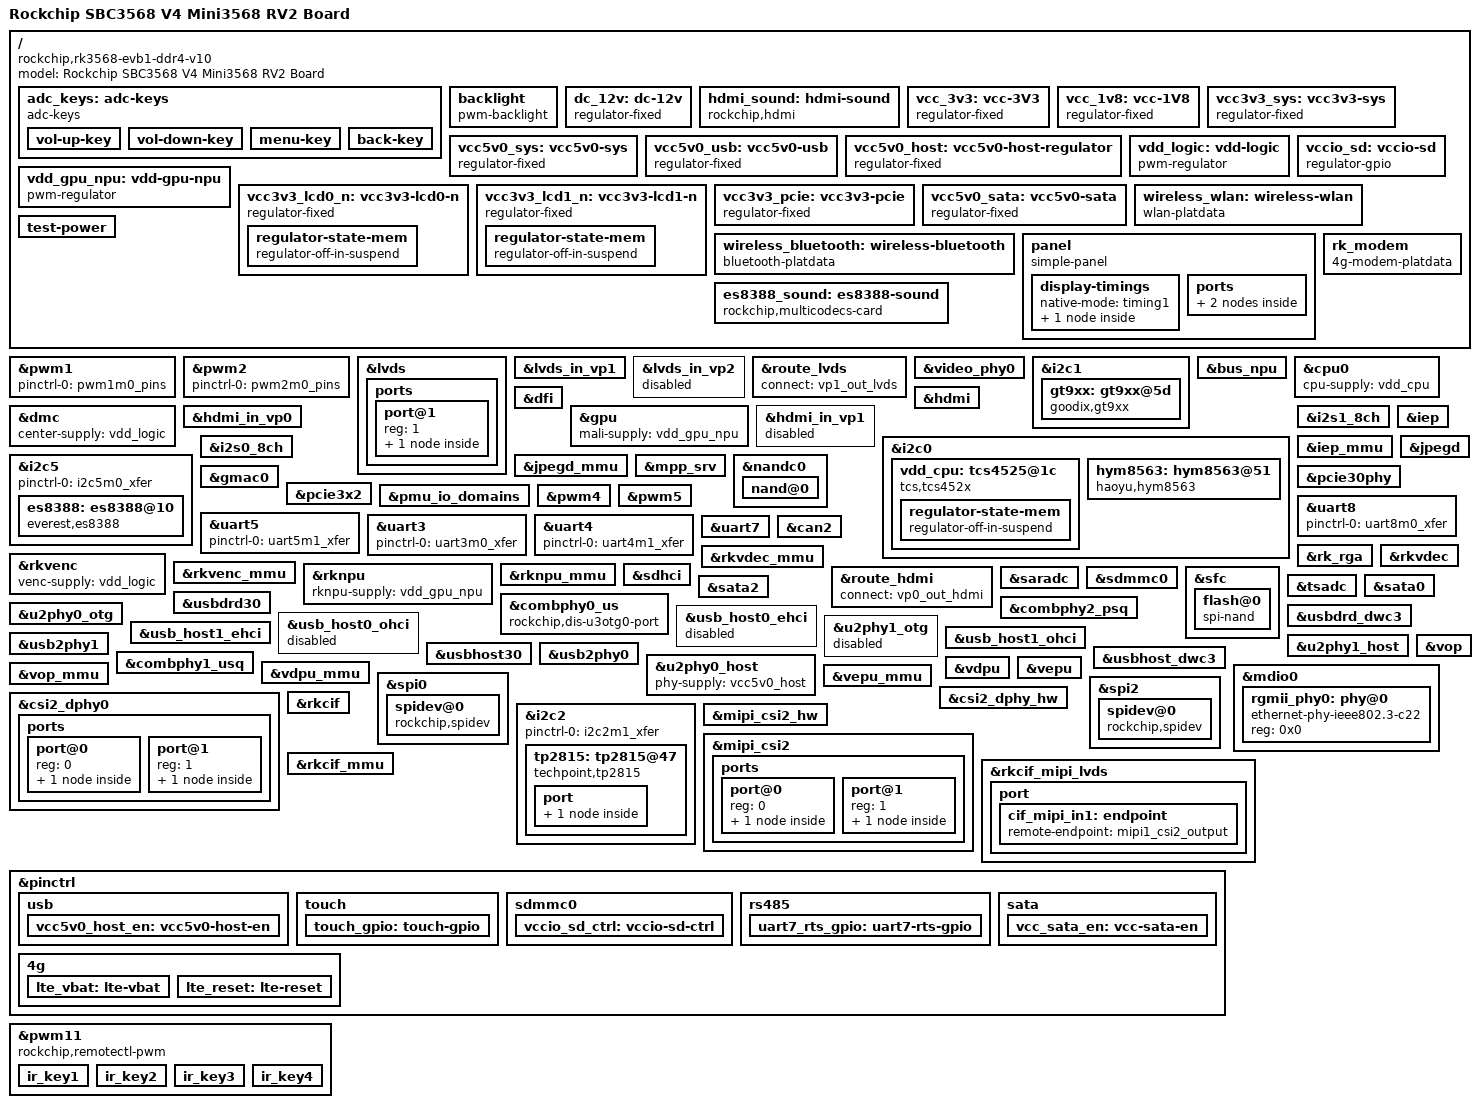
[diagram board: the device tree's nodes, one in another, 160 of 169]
// SPDX-License-Identifier: (GPL-2.0+ OR MIT)
/*
 * Copyright (c) 2020 Rockchip Electronics Co., Ltd.
 *
 */

/dts-v1/;

#include <dt-bindings/gpio/gpio.h>
#include <dt-bindings/pwm/pwm.h>
#include <dt-bindings/pinctrl/rockchip.h>
#include <dt-bindings/input/rk-input.h>
#include <dt-bindings/display/drm_mipi_dsi.h>
#include <dt-bindings/display/rockchip_vop.h>
#include <dt-bindings/display/media-bus-format.h>
#include <dt-bindings/sensor-dev.h>
#include "rk3568.dtsi"
#include "rk3568-linux.dtsi"

/ {
	model = "Rockchip SBC3568 V4 Mini3568 RV2 Board";
	compatible = "rockchip,rk3568-evb1-ddr4-v10", "rockchip,rk3568";
	/delete-node/ chosen;
	
	adc_keys: adc-keys {
		compatible = "adc-keys";
		io-channels = <&saradc 0>;
		io-channel-names = "buttons";
		keyup-threshold-microvolt = <1800000>;
		poll-interval = <100>;

		vol-up-key {
			label = "volume up";
			linux,code = <KEY_VOLUMEUP>;
			press-threshold-microvolt = <1750>;
		};

		vol-down-key {
			label = "volume down";
			linux,code = <KEY_VOLUMEDOWN>;
			press-threshold-microvolt = <297500>;
		};

		menu-key {
			label = "menu";
			linux,code = <KEY_MENU>;
			press-threshold-microvolt = <980000>;
		};

		back-key {
			label = "back";
			linux,code = <KEY_BACK>;
			press-threshold-microvolt = <1305500>;
		};
	};
	
	backlight: backlight {
		compatible = "pwm-backlight";
		pwms = <&pwm4 0 25000 0>;
		brightness-levels = <
			  0  20  20  21  21  22  22  23
			 23  24  24  25  25  26  26  27
			 27  28  28  29  29  30  30  31
			 31  32  32  33  33  34  34  35
			 35  36  36  37  37  38  38  39
			 40  41  42  43  44  45  46  47
			 48  49  50  51  52  53  54  55
			 56  57  58  59  60  61  62  63
			 64  65  66  67  68  69  70  71
			 72  73  74  75  76  77  78  79
			 80  81  82  83  84  85  86  87
			 88  89  90  91  92  93  94  95
			 96  97  98  99 100 101 102 103
			104 105 106 107 108 109 110 111
			112 113 114 115 116 117 118 119
			120 121 122 123 124 125 126 127
			128 129 130 131 132 133 134 135
			136 137 138 139 140 141 142 143
			144 145 146 147 148 149 150 151
			152 153 154 155 156 157 158 159
			160 161 162 163 164 165 166 167
			168 169 170 171 172 173 174 175
			176 177 178 179 180 181 182 183
			184 185 186 187 188 189 190 191
			192 193 194 195 196 197 198 199
			200 201 202 203 204 205 206 207
			208 209 210 211 212 213 214 215
			216 217 218 219 220 221 222 223
			224 225 226 227 228 229 230 231
			232 233 234 235 236 237 238 239
			240 241 242 243 244 245 246 247
			248 249 250 251 252 253 254 255
		>;
		default-brightness-level = <200>;
	};
	
	dc_12v: dc-12v {
		compatible = "regulator-fixed";
		regulator-name = "dc_12v";
		regulator-always-on;
		regulator-boot-on;
		regulator-min-microvolt = <12000000>;
		regulator-max-microvolt = <12000000>;
	};

	hdmi_sound: hdmi-sound {
		status = "disabled";
		compatible = "rockchip,hdmi";
		rockchip,mclk-fs = <128>;
		rockchip,card-name = "rockchip-hdmi";
		rockchip,cpu = <&i2s0_8ch>;
		rockchip,codec = <&hdmi>;
		rockchip,jack-det;
	};

	vcc_3v3: vcc-3V3 {
		compatible = "regulator-fixed";
		regulator-name = "vcc_3V3";
		regulator-always-on;
		regulator-boot-on;
		regulator-min-microvolt = <3300000>;
		regulator-max-microvolt = <3300000>;
		vin-supply = <&vcc3v3_sys>;
	};
	
	vcc_1v8: vcc-1V8 {
		compatible = "regulator-fixed";
		regulator-name = "vcc_1V8";
		regulator-always-on;
		regulator-boot-on;
		regulator-min-microvolt = <1800000>;
		regulator-max-microvolt = <1800000>;
		vin-supply = <&vcc3v3_sys>;
	};
	
	vcc3v3_sys: vcc3v3-sys {
		compatible = "regulator-fixed";
		regulator-name = "vcc3v3_sys";
		regulator-always-on;
		regulator-boot-on;
		regulator-min-microvolt = <3300000>;
		regulator-max-microvolt = <3300000>;
		vin-supply = <&dc_12v>;
	};

	vcc5v0_sys: vcc5v0-sys {
		compatible = "regulator-fixed";
		regulator-name = "vcc5v0_sys";
		regulator-always-on;
		regulator-boot-on;
		regulator-min-microvolt = <5000000>;
		regulator-max-microvolt = <5000000>;
		vin-supply = <&dc_12v>;
	};

	vcc5v0_usb: vcc5v0-usb {
		compatible = "regulator-fixed";
		regulator-name = "vcc5v0_usb";
		regulator-always-on;
		regulator-boot-on;
		regulator-min-microvolt = <5000000>;
		regulator-max-microvolt = <5000000>;
		vin-supply = <&dc_12v>;
	};

	/* usb3.0 host power en */
	vcc5v0_host: vcc5v0-host-regulator {
		compatible = "regulator-fixed";
		regulator-name = "vcc5v0_host";
		regulator-boot-on;
		regulator-always-on;
		regulator-min-microvolt = <5000000>;
		regulator-max-microvolt = <5000000>;
		enable-active-high;
		gpio = <&gpio3 RK_PB5 GPIO_ACTIVE_HIGH>;
		vin-supply = <&vcc5v0_usb>;
		pinctrl-names = "default";
		pinctrl-0 = <&vcc5v0_host_en>;
	};

	vdd_logic: vdd-logic {
		compatible = "pwm-regulator";
		pwms = <&pwm1 0 5000 1>;
		regulator-name = "vdd_logic";
		regulator-min-microvolt = <840000>;
		regulator-max-microvolt = <1040000>;
		regulator-init-microvolt = <900000>;
		regulator-always-on;
		regulator-boot-on;
		regulator-settling-time-up-us = <250>;
		pwm-supply = <&vcc5v0_sys>;
		status = "okay";
	};
	
	vdd_gpu_npu: vdd-gpu-npu {
		compatible = "pwm-regulator";
		pwms = <&pwm2 0 5000 1>;
		regulator-name = "vdd_gpu_npu";
		regulator-min-microvolt = <810000>;
		regulator-max-microvolt = <1150000>;
		regulator-init-microvolt = <900000>;
		regulator-always-on;
		regulator-boot-on;
		regulator-settling-time-up-us = <250>;
		pwm-supply = <&vcc5v0_sys>;
		status = "okay";
	};
	
	/* sd card speed swith */
	vccio_sd: vccio-sd {
  	compatible = "regulator-gpio";
  	regulator-name = "vccio_sd";
  	regulator-type = "voltage";
  	regulator-min-microvolt = <1800000>;
  	regulator-max-microvolt = <3300000>;
  	gpios = <&gpio0 RK_PB7 GPIO_ACTIVE_HIGH>;
//  	gpios-states = <1>;
  	states = <1800000 1>, 
  		       <3300000 0>; 
  	regulator-boot-on;
	  regulator-always-on;
	  pinctrl-names = "default";
	  pinctrl-0 = <&vccio_sd_ctrl>;
};

	vcc3v3_lcd0_n: vcc3v3-lcd0-n {
		compatible = "regulator-fixed";
		regulator-name = "vcc3v3_lcd0_n";
		regulator-boot-on;
		regulator-state-mem {
			regulator-off-in-suspend;
		};
	};

	vcc3v3_lcd1_n: vcc3v3-lcd1-n {
		compatible = "regulator-fixed";
		regulator-name = "vcc3v3_lcd1_n";
		regulator-boot-on;
		regulator-state-mem {
			regulator-off-in-suspend;
		};
	};

/* m.2 power en */	
	vcc3v3_pcie: vcc3v3-pcie {
		compatible = "regulator-fixed";
		regulator-name = "vcc3v3_pcie";
		regulator-min-microvolt = <3300000>;
		regulator-max-microvolt = <3300000>;
		enable-active-high;
		gpio = <&gpio3 RK_PB0 GPIO_ACTIVE_HIGH>;
		startup-delay-us = <5000>;
		pinctrl-names = "default";
	  pinctrl-0 = <&vcc_sata_en>;
	};

/* SATA power en */	
	vcc5v0_sata: vcc5v0-sata {
		compatible = "regulator-fixed";
		regulator-name = "vcc5v0_sata";
		enable-active-high;
		regulator-always-on;
    regulator-boot-on;
		gpio = <&gpio3 RK_PC1 GPIO_ACTIVE_HIGH>;
		startup-delay-us = <5000>;
	};

	wireless_wlan: wireless-wlan {
		compatible = "wlan-platdata";
		rockchip,grf = <&grf>;
		wifi_chip_type = "rtl8723du";
		status = "okay";
	};

	wireless_bluetooth: wireless-bluetooth {
		compatible = "bluetooth-platdata";
		clock-names = "ext_clock";
		status = "okay";
	};

	test-power {
		status = "okay";
	};
	
/* lvds0_ */	
	panel {
		compatible = "simple-panel";
		backlight = <&backlight>;
		power-supply = <&vcc3v3_lcd0_n>;
		enable-delay-ms = <20>;
		prepare-delay-ms = <120>;
		unprepare-delay-ms = <120>;
		disable-delay-ms = <20>;
		bus-format = <MEDIA_BUS_FMT_RGB888_1X24>;	
		rockchip,data-mapping = "vesa";
		width-mm = <217>;
		height-mm = <136>;
		rockchip,output = "lvds";
		status = "okay"; 
		
		display-timings {
			native-mode = <&timing1>;

			timing1: timing1 {
				clock-frequency = <68000000>;
				hactive = <1280>;
				vactive = <800>;
				hback-porch = <100>;
				hfront-porch = <18>;
				vback-porch = <8>;
				vfront-porch = <6>;
				hsync-len = <10>;
				vsync-len = <2>;
				hsync-active = <0>;
				vsync-active = <0>;
				de-active = <0>;
				pixelclk-active = <0>;	
							
			};
		};

		ports {
			#address-cells = <1>;
			#size-cells = <0>;

			port@0 {
				reg = <0>;
				dual-lvds-even-pixels;
				panel_in_lvds: endpoint {
					remote-endpoint = <&lvds_out_panel>;
				};
			};
		};
	};

	es8388_sound: es8388-sound {
		status = "okay";
		compatible = "rockchip,multicodecs-card";
		rockchip,card-name = "rockchip-es8388";
		rockchip,format = "i2s";
		rockchip,mclk-fs = <256>;
		rockchip,cpu = <&i2s1_8ch>;
		rockchip,codec = <&es8388>;
		rockchip,audio-routing =
			"Headphone", "LOUT2",
			"Headphone", "ROUT2",
			"Headphone", "Headphone Power",
			"Headphone", "Headphone Power",
			"LINPUT1", "Main Mic",
			"RINPUT1", "Headset Mic";
		pinctrl-names = "default";
	};
	
	rk_modem {
   	compatible="4g-modem-platdata";
   	pinctrl-names = "default";
    pinctrl-0 = <&lte_vbat &lte_reset>;
   	4G,vbat-gpio =  <&gpio3 RK_PA1 GPIO_ACTIVE_HIGH>;
   	4G,reset-gpio = <&gpio3 RK_PA7 GPIO_ACTIVE_HIGH>;
   	status = "okay";
  	};
};

&pwm1 {
	pinctrl-0 = <&pwm1m0_pins>;
	status = "okay";
};

&pwm2 {
	pinctrl-0 = <&pwm2m0_pins>;
	status = "okay";	
};


/* lvds */	

&backlight {
	status = "okay";
};


&lvds {
	status = "okay"; 

	ports {
		port@1 {
			reg = <1>;

			lvds_out_panel: endpoint {
				remote-endpoint = <&panel_in_lvds>;
			};
		};
	};
};

&lvds_in_vp1 {
	status = "okay";
};

&lvds_in_vp2 {
	status = "disabled";
};

&route_lvds {
	status = "okay";
	connect = <&vp1_out_lvds>;	
};

/* lvds phy*/	
&video_phy0 {
	status = "okay";
};

&i2c1 {
	status = "okay";
	gt9xx: gt9xx@5d {
		compatible = "goodix,gt9xx";
		reg = <0x5d>;
		pinctrl-names = "default";
		pinctrl-0 = <&touch_gpio>;
		touch-gpio = <&gpio0 RK_PC4 GPIO_ACTIVE_LOW>;
		reset-gpio = <&gpio0 RK_PA5 GPIO_ACTIVE_LOW>;
		max-x = <1280>;
		max-y = <800>;
		tp-size = <89>;
	};
};


&bus_npu {
	bus-supply = <&vdd_logic>;
	pvtm-supply = <&vdd_cpu>;
	status = "okay";
};

&cpu0 {
	cpu-supply = <&vdd_cpu>;
};

&dfi {
	status = "okay";
};

&dmc {
	center-supply = <&vdd_logic>;
	status = "okay";
};


&gpu {
	mali-supply = <&vdd_gpu_npu>;
	status = "okay";
};

&hdmi {
	status = "okay";
	rockchip,phy-table =
		<92812500  0x8009 0x0000 0x0270>,
		<165000000 0x800b 0x0000 0x026d>,
		<185625000 0x800b 0x0000 0x01ed>,
		<297000000 0x800b 0x0000 0x01ad>,
		<594000000 0x8029 0x0000 0x0088>,
		<000000000 0x0000 0x0000 0x0000>;
};

&hdmi_in_vp0 {
	status = "okay";
};

&hdmi_in_vp1 {
	status = "disabled";
};

&hdmi_sound {
	status = "okay";
};

&i2c0 {
	status = "okay";

	vdd_cpu: tcs4525@1c {
		compatible = "tcs,tcs452x";
		reg = <0x1c>;
		vin-supply = <&vcc5v0_sys>;
		regulator-compatible = "fan53555-reg";
		regulator-name = "vdd_cpu";
		regulator-min-microvolt = <712500>;
		regulator-max-microvolt = <1390000>;
		regulator-init-microvolt = <900000>;
		regulator-ramp-delay = <2300>;
		fcs,suspend-voltage-selector = <1>;
		regulator-boot-on;
		regulator-always-on;
		regulator-state-mem {
			regulator-off-in-suspend;
		};
	};
	
	hym8563: hym8563@51 {
		status = "okay";
		compatible = "haoyu,hym8563";
		reg = <0x51>;
		#clock-cells = <0>;
		interrupt-parent = <&gpio0>;
		interrupts = <27 IRQ_TYPE_EDGE_FALLING>;
		clock-frequency = <32768>;
		wakeup-source = <1>;
	};
};


/* headset */
&i2c5{
	status = "okay";
	pinctrl-names = "default";
	pinctrl-0 = <&i2c5m0_xfer>;
	
	es8388: es8388@10 {
		status = "okay";
		#sound-dai-cells = <0>;
		compatible = "everest,es8388", "everest,es8323";
		reg = <0x10>;
		clocks = <&cru I2S1_MCLKOUT>;
		clock-names = "mclk";
		assigned-clocks = <&cru I2S1_MCLKOUT>, <&cru I2S1_MCLK_TX_IOE>;
		assigned-clock-rates = <12288000>;
		assigned-clock-parents = <&cru I2S1_MCLKOUT_TX>, <&cru I2S1_MCLKOUT_TX>;
		pinctrl-names = "default";
		pinctrl-0 = <&i2s1m0_mclk>;
		everest,differential-input = <1>;
		everest,dac-output = <2>;
	};
};

&i2s1_8ch {
	status = "okay";
	rockchip,trcm-sync-tx-only;
	pinctrl-names = "default";
	pinctrl-0 = <&i2s1m0_sclktx
		     &i2s1m0_lrcktx
		     &i2s1m0_sdi0
		     &i2s1m0_sdo0>;
};

/* hdmi sound phy */
&i2s0_8ch {
	status = "okay";
};

&iep {
	status = "okay";
};

&iep_mmu {
	status = "okay";
};

&jpegd {
	status = "okay";
};

&jpegd_mmu {
	status = "okay";
};

&mpp_srv {
	status = "okay";
};

&nandc0 {
	#address-cells = <1>;
	#size-cells = <0>;
	status = "okay";

	nand@0 {
		reg = <0>;
		nand-bus-width = <8>;
		nand-ecc-mode = "hw";
		nand-ecc-strength = <16>;
		nand-ecc-step-size = <1024>;
	};
};

/***Net interface***/
&gmac0 {
	phy-mode = "rgmii";
	clock_in_out = "output";

	snps,reset-gpio = <&gpio0 RK_PA3 GPIO_ACTIVE_LOW>;
	snps,reset-active-low;
	/* Reset time is 20ms, 100ms for rtl8211f */
	snps,reset-delays-us = <0 20000 100000>;

	assigned-clocks = <&cru SCLK_GMAC0_RX_TX>, <&cru SCLK_GMAC0>;
	assigned-clock-parents = <&cru SCLK_GMAC0_RGMII_SPEED>, <&cru CLK_MAC0_2TOP>;
	assigned-clock-rates = <0>, <125000000>;

	pinctrl-names = "default";
	pinctrl-0 = <&gmac0_miim
		     &gmac0_tx_bus2
		     &gmac0_rx_bus2
		     &gmac0_rgmii_clk
		     &gmac0_rgmii_bus>;

	tx_delay = <0x3c>;
	rx_delay = <0x2f>;

	phy-handle = <&rgmii_phy0>;
	status = "okay";
};

/* m.2 phy */
&pcie30phy {
	status = "okay";
};

/* m.2 ssd */
&pcie3x2 {
	reset-gpios = <&gpio0 RK_PC6 GPIO_ACTIVE_HIGH>;
	vpcie3v3-supply = <&vcc3v3_pcie>;
	status = "okay";
};


 /*
  * There are 10 independent IO domains in RK3566/RK3568, including PMUIO[0:2] and VCCIO[1:7].
  * 1/ PMUIO0 and PMUIO1 are fixed-level power domains which cannot be configured;
  * 2/ PMUIO2 and VCCIO1,VCCIO[3:7] domains require that their hardware power supply voltages
  *    must be consistent with the software configuration correspondingly
  *	a/ When the hardware IO level is connected to 1.8V, the software voltage configuration
  *	   should also be configured to 1.8V accordingly;
  *	b/ When the hardware IO level is connected to 3.3V, the software voltage configuration
  *	   should also be configured to 3.3V accordingly;
  * 3/ VCCIO2 voltage control selection (0xFDC20140)
  *	BIT[0]: 0x0: from GPIO_0A7 (default)
  *	BIT[0]: 0x1: from GRF
  *    Default is determined by Pin FLASH_VOL_SEL/GPIO0_A7:
  *	L:VCCIO2 must supply 3.3V
  *	H:VCCIO2 must supply 1.8V
  */
&pmu_io_domains {
	status = "okay";
	pmuio2-supply = <&vcc_3v3>;
	vccio1-supply = <&vcc_3v3>;
	vccio3-supply = <&vccio_sd>;
	vccio4-supply = <&vcc_1v8>;
	vccio5-supply = <&vcc_3v3>;
	vccio6-supply = <&vcc_1v8>;
	vccio7-supply = <&vcc_3v3>;
};

&pwm4 {
	status = "okay";
};

&pwm5 {
	status = "okay";
};


/*  uart   */
&uart8 {
  status = "okay";
  pinctrl-names = "default";
  pinctrl-0 = <&uart8m0_xfer>;
};

&uart5 {
  status = "okay";
  pinctrl-names = "default";
  pinctrl-0 = <&uart5m1_xfer>;
};

&uart3 {
  status = "okay";
  pinctrl-names = "default";
  pinctrl-0 = <&uart3m0_xfer>;
};

&uart4 {
  status = "okay";
  pinctrl-names = "default";
  pinctrl-0 = <&uart4m1_xfer>;
};

/* rs485 */
&uart7 {
  status = "okay";
  pinctrl-names = "default";
  pinctrl-0 = <&uart7m1_xfer &uart7_rts_gpio>;
  rs485-de-gpios = <&gpio4 RK_PC2 GPIO_ACTIVE_HIGH>;
  linux,rs485-enabled-at-boot-time;
  //rs485-rts-active-low;
};

/* can */
&can2 {
  assigned-clocks = <&cru CLK_CAN2>;
  assigned-clock-rates = <150000000>;
  pinctrl-names = "default";
  pinctrl-0 = <&can2m1_pins>;
  status = "okay";
};



&rk_rga {
	status = "okay";
};

&rkvdec {
	status = "okay";
};

&rkvdec_mmu {
	status = "okay";
};

&rkvenc {
	venc-supply = <&vdd_logic>;
	status = "okay";
};

&rkvenc_mmu {
	status = "okay";
};

&rknpu {
	rknpu-supply = <&vdd_gpu_npu>;
	status = "okay";
};

&rknpu_mmu {
	status = "okay";
};

&route_hdmi {
	status = "okay";
	connect = <&vp0_out_hdmi>;
};

&saradc {
	status = "okay";
};

&sdhci {
	bus-width = <8>;
	no-sdio;
	no-sd;
	non-removable;
	max-frequency = <200000000>;
	full-pwr-cycle-in-suspend;
	status = "okay";
};

/* sd card */
&sdmmc0 {
	max-frequency = <150000000>;
	no-sdio;
	no-mmc;
	bus-width = <4>;
	cap-mmc-highspeed;
	cap-sd-highspeed;
	disable-wp;
	sd-uhs-sdr104;
	vmmc-supply = <&vcc_3v3>;
	vqmmc-supply = <&vccio_sd>;
	pinctrl-names = "default";
	pinctrl-0 = <&sdmmc0_bus4 &sdmmc0_clk &sdmmc0_cmd &sdmmc0_det>;
	status = "okay";
};

&sfc {
	status = "okay";

	flash@0 {
		compatible = "spi-nand";
		reg = <0>;
		spi-max-frequency = <75000000>;
		spi-rx-bus-width = <4>;
		spi-tx-bus-width = <1>;
	};
};


&tsadc {
	status = "okay";
};

/* sata0 */
&sata0 {
  status = "okay";
};

/* USB 3.0 OTG/SATA Combo PHY_0 */
&combphy0_us {
	rockchip,dis-u3otg0-port;
	status = "okay";
};

/* sata2 */
&sata2 {
  status = "okay";
};

/* sata2 phy*/
&combphy2_psq {
	status = "okay";
};


/* USB 3.0 OTG controller */
&usbdrd30 {
	status = "okay";
};

&u2phy0_otg {
	status = "okay";
};

/* USB OTG */
&usbdrd_dwc3 {  
	phys = <&u2phy0_otg>;
  phy-names = "usb2-phy";
  extcon = <&usb2phy0>;
  maximum-speed = "high-speed";
  snps,dis_u2_susphy_quirk;
  snps,usb2-lpm-disable;
  status = "okay";
};


/* USB 2.0 Host_2 null */
&usb_host0_ehci {
	status = "disabled";
};

&usb_host0_ohci {
	status = "disabled";
};

&u2phy1_otg {
	status = "disabled";
};

/* USB 2.0 Host_3 */
/* mini pcie 4G   */

&usb_host1_ehci {
	status = "okay";
};

&usb_host1_ohci {
	status = "okay";
};

&usb2phy1 {
	status = "okay";
};

&u2phy1_host {
	status = "okay";
};



/* usb3.0 host */
&usbhost30 {
	status = "okay";
};

&usbhost_dwc3 {
	status = "okay";
};

&usb2phy0 {
	status = "okay";
};

&u2phy0_host {
	phy-supply = <&vcc5v0_host>;
	status = "okay";
};

/* USB 3.0 Host/SATA/QSGMII Combo PHY_1 */
&combphy1_usq {
	status = "okay";
};

&vdpu {
	status = "okay";
};

&vdpu_mmu {
	status = "okay";
};

&vepu {
	status = "okay";
};

&vepu_mmu {
	status = "okay";
};

&vop {
	status = "okay";
	vop-supply = <&vdd_logic>;
	assigned-clocks = <&cru DCLK_VOP0>, <&cru DCLK_VOP1>, <&cru DCLK_VOP2>;
	assigned-clock-parents = <&pmucru PLL_HPLL>, <&cru PLL_VPLL>, <&cru PLL_GPLL>;
};

&vop_mmu {
	status = "okay";
};


/* ethernet */
&gmac0 {
	phy-mode = "rgmii";
	clock_in_out = "output";

	snps,reset-gpio = <&gpio0 RK_PA3 GPIO_ACTIVE_LOW>;
	snps,reset-active-low;
	/* Reset time is 20ms, 100ms for rtl8211f */
	snps,reset-delays-us = <0 20000 100000>;

	assigned-clocks = <&cru SCLK_GMAC0_RX_TX>, <&cru SCLK_GMAC0>;
	assigned-clock-parents = <&cru SCLK_GMAC0_RGMII_SPEED>, <&cru CLK_MAC0_2TOP>;
	assigned-clock-rates = <0>, <125000000>;

	pinctrl-names = "default";
	pinctrl-0 = <&gmac0_miim
		     &gmac0_tx_bus2
		     &gmac0_rx_bus2
		     &gmac0_rgmii_clk
		     &gmac0_rgmii_bus>;

	tx_delay = <0x3c>;
	rx_delay = <0x2f>;

	phy-handle = <&rgmii_phy0>;
	status = "okay";
};

&mdio0 {
	rgmii_phy0: phy@0 {
		compatible = "ethernet-phy-ieee802.3-c22";
		reg = <0x0>;
	};
};

&spi0 {
  status = "okay";
  #address-cells = <1>;
  #size-cells = <0>;
  pinctrl-names = "default";
  pinctrl-0 = <&spi0m1_cs0 &spi0m1_pins>;
  max-freq = <50000000>;

   spidev@0 {
    compatible = "rockchip,spidev";
    status = "okay";
    reg = <0>;
    spi-max-frequency = <50000000>;
  };
};

&spi2 {
  status = "okay";
  #address-cells = <1>;
  #size-cells = <0>;
  pinctrl-names = "default";
  pinctrl-0 = <&spi2m1_cs0 &spi2m1_pins>;
  max-freq = <50000000>;

  spidev@0 {
    compatible = "rockchip,spidev";
    status = "okay";
    reg = <0>;
    spi-max-frequency = <50000000>;
  };
}; 

/* tp2855 */
&csi2_dphy0 {
	status = "okay";

	ports {
		#address-cells = <1>;
		#size-cells = <0>;
		port@0 {
			reg = <0>;
			#address-cells = <1>;
			#size-cells = <0>;

			mipi_dphy0_in_tp2815: endpoint@1 {
				reg = <1>;
				remote-endpoint = <&tp2815_out0>;
				data-lanes = <1 2 3 4>;
			};
		};
		port@1 {
			reg = <1>;
			#address-cells = <1>;
			#size-cells = <0>;

			csidphy0_out: endpoint@0 {
				reg = <0>;
				remote-endpoint = <&mipi1_csi2_input>;
			};
		};
	};
};

&csi2_dphy_hw {
	status = "okay";
};

&i2c2 {
	status = "okay";
	pinctrl-names = "default";
  pinctrl-0 = <&i2c2m1_xfer>;
	tp2815: tp2815@47 {
		compatible = "techpoint,tp2815";
		status = "okay";
		reg = <0x47>;
		clocks = <&cru CLK_CIF_OUT>;
		clock-names = "xvclk";
		power-domains = <&power RK3568_PD_VI>;
		reset-gpios = <&gpio4 RK_PB1 GPIO_ACTIVE_LOW>;
		rockchip,camera-module-index = <0>;
		rockchip,camera-module-facing = "back";
		rockchip,camera-module-name = "default";
		rockchip,camera-module-lens-name = "default";

		port {
					tp2815_out0: endpoint {
									remote-endpoint = < &mipi_dphy0_in_tp2815>;
									data-lanes = <1 2 3 4>;
						};
				};
		};
};


&mipi_csi2_hw {
  status = "okay";
};

&mipi_csi2 {
	status = "okay";

	ports {
		#address-cells = <1>;
		#size-cells = <0>;

		port@0 {
			reg = <0>;
			#address-cells = <1>;
			#size-cells = <0>;

			mipi1_csi2_input: endpoint@1 {
				reg = <1>;
				remote-endpoint = <&csidphy0_out>;
			};
		};

		port@1 {
			reg = <1>;
			#address-cells = <1>;
			#size-cells = <0>;

			mipi1_csi2_output: endpoint@0 {
				reg = <0>;
				remote-endpoint = <&cif_mipi_in1>;
			};
		};
	};
};

&rkcif {
	status = "okay";
};

&rkcif_mipi_lvds {
	status = "okay";

	port {
		cif_mipi_in1: endpoint {
			remote-endpoint = <&mipi1_csi2_output>;
		};
	};
};

&rkcif_mmu {
	status = "okay";
};
 

&pinctrl {

	usb {
		vcc5v0_host_en: vcc5v0-host-en {
			rockchip,pins = <3 RK_PB5 RK_FUNC_GPIO &pcfg_pull_none>;
		};
	};

	touch {
		touch_gpio: touch-gpio {
			rockchip,pins =
				<0 RK_PC4 RK_FUNC_GPIO &pcfg_pull_up>,
				<0 RK_PA5 RK_FUNC_GPIO &pcfg_pull_none>;
		};
	};
	
	sdmmc0 {
		vccio_sd_ctrl: vccio-sd-ctrl {
			rockchip,pins = <0 RK_PB7 RK_FUNC_GPIO &pcfg_pull_none>;
		};
	}; 
	
	rs485 {
		uart7_rts_gpio: uart7-rts-gpio {
			rockchip,pins = <4 RK_PC2 RK_FUNC_GPIO &pcfg_pull_none>;
		};
	};
	
	sata {
		vcc_sata_en: vcc-sata-en {
			rockchip,pins = <3 RK_PC1 RK_FUNC_GPIO &pcfg_pull_none>;
		};
	}; 
	
	4g {
    lte_vbat: lte-vbat {
      rockchip,pins = <3 RK_PA1 RK_FUNC_GPIO &pcfg_pull_none>;
   };
    lte_reset: lte-reset {
      rockchip,pins = <3 RK_PA7 RK_FUNC_GPIO &pcfg_pull_none>;
   };
  };
};


/* IR */
&pwm11 {
	status = "okay";

	compatible = "rockchip,remotectl-pwm";
	remote_pwm_id = <11>;
	handle_cpu_id = <1>;
	remote_support_psci = <0>;
	pinctrl-names = "default";
	pinctrl-0 = <&pwm11m0_pins>;

	ir_key1 {
		rockchip,usercode = <0x4040>;
		rockchip,key_table =
			<0xf2	KEY_REPLY>,
			<0xba	KEY_BACK>,
			<0xf4	KEY_UP>,
			<0xf1	KEY_DOWN>,
			<0xef	KEY_LEFT>,
			<0xee	KEY_RIGHT>,
			<0xbd	KEY_HOME>,
			<0xea	KEY_VOLUMEUP>,
			<0xe3	KEY_VOLUMEDOWN>,
			<0xe2	KEY_SEARCH>,
			<0xb2	KEY_POWER>,
			<0xbc	KEY_MUTE>,
			<0xec	KEY_MENU>,
			<0xbf	0x190>,
			<0xe0	0x191>,
			<0xe1	0x192>,
			<0xe9	183>,
			<0xe6	248>,
			<0xe8	185>,
			<0xe7	186>,
			<0xf0	388>,
			<0xbe	0x175>;
	};

	ir_key2 {
		rockchip,usercode = <0xff00>;
		rockchip,key_table =
			<0xf9	KEY_HOME>,
			<0xbf	KEY_BACK>,
			<0xfb	KEY_MENU>,
			<0xaa	KEY_REPLY>,
			<0xb9	KEY_UP>,
			<0xe9	KEY_DOWN>,
			<0xb8	KEY_LEFT>,
			<0xea	KEY_RIGHT>,
			<0xeb	KEY_VOLUMEDOWN>,
			<0xef	KEY_VOLUMEUP>,
			<0xf7	KEY_MUTE>,
			<0xe7	KEY_POWER>,
			<0xfc	KEY_POWER>,
			<0xa9	KEY_VOLUMEDOWN>,
			<0xa8	KEY_VOLUMEDOWN>,
			<0xe0	KEY_VOLUMEDOWN>,
			<0xa5	KEY_VOLUMEDOWN>,
			<0xab	183>,
			<0xb7	388>,
			<0xe8	388>,
			<0xf8	184>,
			<0xaf	185>,
			<0xed	KEY_VOLUMEDOWN>,
			<0xee	186>,
			<0xb3	KEY_VOLUMEDOWN>,
			<0xf1	KEY_VOLUMEDOWN>,
			<0xf2	KEY_VOLUMEDOWN>,
			<0xf3	KEY_SEARCH>,
			<0xb4	KEY_VOLUMEDOWN>,
			<0xbe	KEY_SEARCH>;
	};

	ir_key3 {
		rockchip,usercode = <0x1dcc>;
		rockchip,key_table =
			<0xee	KEY_REPLY>,
			<0xf0	KEY_BACK>,
			<0xf8	KEY_UP>,
			<0xbb	KEY_DOWN>,
			<0xef	KEY_LEFT>,
			<0xed	KEY_RIGHT>,
			<0xfc	KEY_HOME>,
			<0xf1	KEY_VOLUMEUP>,
			<0xfd	KEY_VOLUMEDOWN>,
			<0xb7	KEY_SEARCH>,
			<0xff	KEY_POWER>,
			<0xf3	KEY_MUTE>,
			<0xbf	KEY_MENU>,
			<0xf9	0x191>,
			<0xf5	0x192>,
			<0xb3	388>,
			<0xbe	KEY_1>,
			<0xba	KEY_2>,
			<0xb2	KEY_3>,
			<0xbd	KEY_4>,
			<0xf9	KEY_5>,
			<0xb1	KEY_6>,
			<0xfc	KEY_7>,
			<0xf8	KEY_8>,
			<0xb0	KEY_9>,
			<0xb6	KEY_0>,
			<0xb5	KEY_BACKSPACE>;
	};
	ir_key4 {
		rockchip,usercode = <0xfe01>;
		rockchip,key_table =
			<0xbf	KEY_BACK>,
			<0xb9	KEY_UP>,
			<0xe9	KEY_DOWN>,
			<0xb8	KEY_LEFT>,
			<0xea	KEY_RIGHT>,
			<0xf9	KEY_HOME>,
			<0xef	KEY_VOLUMEUP>,
			<0xeb	KEY_VOLUMEDOWN>,
			<0xfb	KEY_SEARCH>,
			<0xe7	KEY_POWER>,
			<0xaa	KEY_ENTER>,
			<0xe8	KEY_MENU>;
	};
};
